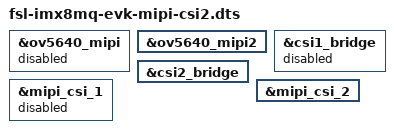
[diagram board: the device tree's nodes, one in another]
/*
 * Copyright 2017 NXP
 *
 * This program is free software; you can redistribute it and/or
 * modify it under the terms of the GNU General Public License
 * as published by the Free Software Foundation; either version 2
 * of the License, or (at your option) any later version.
 *
 * This program is distributed in the hope that it will be useful,
 * but WITHOUT ANY WARRANTY; without even the implied warranty of
 * MERCHANTABILITY or FITNESS FOR A PARTICULAR PURPOSE.  See the
 * GNU General Public License for more details.
 */

#include "fsl-imx8mq-evk.dts"

&ov5640_mipi {
	status = "disabled";
};

&ov5640_mipi2 {
	status = "okay";
};

&csi1_bridge {
	status = "disabled";
};

&csi2_bridge {
	status = "okay";
};

&mipi_csi_1 {
	status = "disabled";
};
&mipi_csi_2 {
	status = "okay";
};
